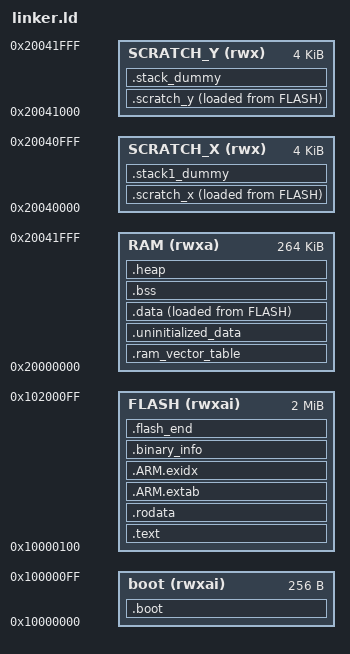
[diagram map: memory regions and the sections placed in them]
ENTRY(resetHandler)
MEMORY {
    boot    (rwxai)     : ORIGIN = 0x10000000, LENGTH = 256
    FLASH   (rwxai)     : ORIGIN = 0x10000100, LENGTH = 2048k
    RAM     (rwxa)      : ORIGIN = 0x20000000, LENGTH = 264k
    SCRATCH_X(rwx) : ORIGIN = 0x20040000, LENGTH = 4k
    SCRATCH_Y(rwx) : ORIGIN = 0x20041000, LENGTH = 4k
}



SECTIONS {
    .boot :
    {
        __boot2_start__ = .;
        KEEP(*(.boot))
        __boot2_end__ = .;
    } > boot

    .text :
    {
        . = ALIGN(4);
        __logical_binary_start = .;
        KEEP (*(.vectors))
        __vectors_end = .;
        KEEP (*(.binary_info_header))
        __binary_info_header_end = .;
        KEEP (*(.embedded_block))
        __embedded_block_end = .;
        KEEP (*(.reset))
        /* TODO revisit this now memset/memcpy/float in ROM */
        /* bit of a hack right now to exclude all floating point and time critical (e.g. memset, memcpy) code from
         * FLASH ... we will include any thing excluded here in .data below by default */
        *(.init)
        *(EXCLUDE_FILE(*libgcc.a: *libc.a:*lib_a-mem*.o *libm.a:) .text*)
        *(.fini)
        /* Pull all c'tors into .text */
        *crtbegin.o(.ctors)
        *crtbegin?.o(.ctors)
        *(EXCLUDE_FILE(*crtend?.o *crtend.o) .ctors)
        *(SORT(.ctors.*))
        *(.ctors)
        /* Followed by destructors */
        *crtbegin.o(.dtors)
        *crtbegin?.o(.dtors)
        *(EXCLUDE_FILE(*crtend?.o *crtend.o) .dtors)
        *(SORT(.dtors.*))
        *(.dtors)

        . = ALIGN(4);
        /* preinit data */
        PROVIDE_HIDDEN (__preinit_array_start = .);
        KEEP(*(SORT(.preinit_array.*)))
        KEEP(*(.preinit_array))
        PROVIDE_HIDDEN (__preinit_array_end = .);

        . = ALIGN(4);
        /* init data */
        PROVIDE_HIDDEN (__init_array_start = .);
        KEEP(*(SORT(.init_array.*)))
        KEEP(*(.init_array))
        PROVIDE_HIDDEN (__init_array_end = .);

        . = ALIGN(4);
        /* finit data */
        PROVIDE_HIDDEN (__fini_array_start = .);
        *(SORT(.fini_array.*))
        *(.fini_array)
        PROVIDE_HIDDEN (__fini_array_end = .);
        *(.text)

        *(.eh_frame*)
        . = ALIGN(4);
    } > FLASH


    .rodata : {
        *(EXCLUDE_FILE(*libgcc.a: *libc.a:*lib_a-mem*.o *libm.a:) .rodata*)
        . = ALIGN(4);
        *(SORT_BY_ALIGNMENT(SORT_BY_NAME(.flashdata*)))
        . = ALIGN(4);
    } > FLASH


    .ARM.extab :
    {
        *(.ARM.extab* .gnu.linkonce.armextab.*)
    } > FLASH

    __exidx_start = .;
    .ARM.exidx :
    {
        *(.ARM.exidx* .gnu.linkonce.armexidx.*)
    } > FLASH
    __exidx_end = .;

    /* Machine inspectable binary information */
    . = ALIGN(4);
    __binary_info_start = .;
    .binary_info :
    {
        KEEP(*(.binary_info.keep.*))
        *(.binary_info.*)
    } > FLASH
    __binary_info_end = .;
    . = ALIGN(4);

    .ram_vector_table (NOLOAD): {
        *(.ram_vector_table)
    } > RAM

    .uninitialized_data (NOLOAD): {
        . = ALIGN(4);
        *(.uninitialized_data*)
    } > RAM



    .data :
    {
        . = ALIGN(4);
        _sdata = .;
        *(vtable)

        *(.time_critical*)

        /* remaining .text and .rodata; i.e. stuff we exclude above because we want it in RAM */
        *(.text*)
        *(.rodata*)

        *(.data*)

        *(.after_data.*)
        /* preinit data */
        PROVIDE_HIDDEN (__mutex_array_start = .);
        KEEP(*(SORT(.mutex_array.*)))
        KEEP(*(.mutex_array))
        PROVIDE_HIDDEN (__mutex_array_end = .);
        *(.jcr)
        . = ALIGN(4);
        _edata = .;
    }  > RAM AT > FLASH

    _sidata = LOADADDR(.data);

    .bss :
    {
        . = ALIGN(4);
        _sbss = .; 
        *(.bss*)
        *(.COMMON)
        . = ALIGN(4);
        _ebss = .;
    } > RAM


    .heap (NOLOAD):
    {
        __end__ = .;
        end = __end__;
        KEEP(*(.heap*))
    } > RAM
    __HeapLimit = ORIGIN(RAM) + LENGTH(RAM);






        /* Start and end symbols must be word-aligned */
    .scratch_x : {
        __scratch_x_start__ = .;
        *(.scratch_x.*)
        . = ALIGN(4);
        __scratch_x_end__ = .;
    } > SCRATCH_X AT > FLASH
    __scratch_x_source__ = LOADADDR(.scratch_x);

    .scratch_y : {
        __scratch_y_start__ = .;
        *(.scratch_y.*)
        . = ALIGN(4);
        __scratch_y_end__ = .;
    } > SCRATCH_Y AT > FLASH
    __scratch_y_source__ = LOADADDR(.scratch_y);

    /* .stack*_dummy section doesn't contains any symbols. It is only
     * used for linker to calculate size of stack sections, and assign
     * values to stack symbols later
     *
     * stack1 section may be empty/missing if platform_launch_core1 is not used */

    /* by default we put core 0 stack at the end of scratch Y, so that if core 1
     * stack is not used then all of SCRATCH_X is free.
     */
    .stack1_dummy (NOLOAD):
    {
        *(.stack1*)
    } > SCRATCH_X
    .stack_dummy (NOLOAD):
    {
        KEEP(*(.stack*))
    } > SCRATCH_Y

    .flash_end : {
        KEEP(*(.embedded_end_block*))
        PROVIDE(__flash_binary_end = .);
    } > FLASH

    /* stack limit is poorly named, but historically is maximum heap ptr */
    __StackLimit = ORIGIN(RAM) + LENGTH(RAM);
    __StackOneTop = ORIGIN(SCRATCH_X) + LENGTH(SCRATCH_X);
    __StackTop = ORIGIN(SCRATCH_Y) + LENGTH(SCRATCH_Y);
    __StackOneBottom = __StackOneTop - SIZEOF(.stack1_dummy);
    __StackBottom = __StackTop - SIZEOF(.stack_dummy);
    PROVIDE(__stack = __StackTop);


}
